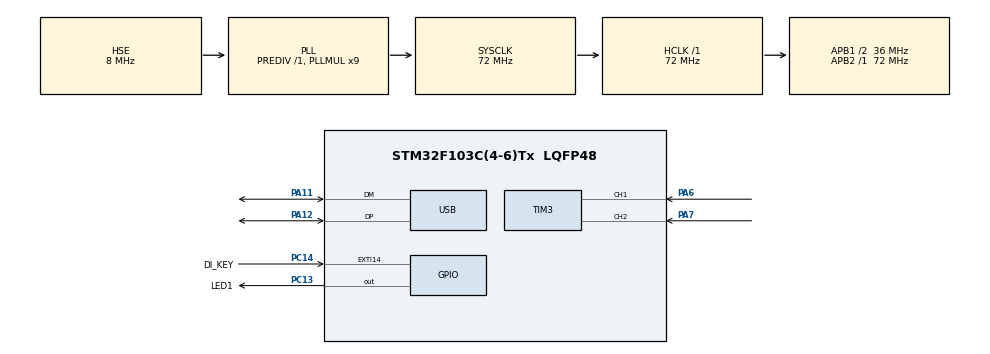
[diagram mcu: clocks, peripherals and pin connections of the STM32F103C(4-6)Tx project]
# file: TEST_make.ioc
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Mcu.Family=STM32F1
Mcu.Name=STM32F103C(4-6)Tx
Mcu.Package=LQFP48
NVIC.EXTI15_10_IRQn=true\:0\:0\:false\:false\:true\:true\:true\:true
NVIC.PriorityGroup=NVIC_PRIORITYGROUP_4
NVIC.USB_LP_CAN1_RX0_IRQn=true\:0\:0\:false\:false\:true\:false\:true\:true
PA11.Mode=Device
PA11.Signal=USB_DM
PA12.Mode=Device
PA12.Signal=USB_DP
PA13.Mode=Serial_Wire
PA13.Signal=SYS_JTMS-SWDIO
PA14.Mode=Serial_Wire
PA14.Signal=SYS_JTCK-SWCLK
PA6.Signal=S_TIM3_CH1
PA7.Signal=S_TIM3_CH2
PC13-TAMPER-RTC.GPIO_Label=LED1
PC13-TAMPER-RTC.GPIO_Speed=GPIO_SPEED_FREQ_HIGH
PC13-TAMPER-RTC.Signal=GPIO_Output
PC14-OSC32_IN.GPIO_Label=DI_KEY
PC14-OSC32_IN.GPIO_ModeDefaultEXTI=GPIO_MODE_IT_RISING
PC14-OSC32_IN.GPIO_PuPd=GPIO_PULLUP
PC14-OSC32_IN.Signal=GPXTI14
PD0-OSC_IN.Mode=HSE-External-Oscillator
PD0-OSC_IN.Signal=RCC_OSC_IN
PD1-OSC_OUT.Mode=HSE-External-Oscillator
PD1-OSC_OUT.Signal=RCC_OSC_OUT
ProjectManager.HeapSize=0x200
ProjectManager.StackSize=0x400
ProjectManager.TargetToolchain=CMake
RCC.AHBFreq_Value=72000000
RCC.APB1CLKDivider=RCC_HCLK_DIV2
RCC.APB1Freq_Value=36000000
RCC.APB1TimFreq_Value=72000000
RCC.APB2Freq_Value=72000000
RCC.APB2TimFreq_Value=72000000
RCC.HCLKFreq_Value=72000000
RCC.PLLMUL=RCC_PLL_MUL9
RCC.PLLSourceVirtual=RCC_PLLSOURCE_HSE
RCC.SYSCLKFreq_VALUE=72000000
RCC.SYSCLKSource=RCC_SYSCLKSOURCE_PLLCLK
RCC.USBFreq_Value=48000000
RCC.USBPrescaler=RCC_USBCLKSOURCE_PLL_DIV1_5
SH.S_TIM3_CH1.0=TIM3_CH1,Encoder_Interface
SH.S_TIM3_CH2.0=TIM3_CH2,Encoder_Interface
TIM3.EncoderMode=TIM_ENCODERMODE_TI12
TIM3.IC1Filter=15
USB_DEVICE.CLASS_NAME_FS=CDC
USB_DEVICE.VirtualMode=Cdc
USB_DEVICE.VirtualModeFS=Cdc_FS
VP_USB_DEVICE_VS_USB_DEVICE_CDC_FS.Mode=CDC_FS
board=custom

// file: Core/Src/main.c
/* USER CODE BEGIN Header */
/**
  ******************************************************************************
  * @file           : main.c
  * @brief          : Main program body
  ******************************************************************************
  * @attention
  *
  * Copyright (c) 2026 STMicroelectronics.
  * All rights reserved.
  *
  * This software is licensed under terms that can be found in the LICENSE file
  * in the root directory of this software component.
  * If no LICENSE file comes with this software, it is provided AS-IS.
  *
  ******************************************************************************
  */
/* USER CODE END Header */
#include "main.h"
#include "usb_device.h"

/* USER CODE BEGIN Includes */
#include "usbd_cdc_if.h"
#include "usbd_cdc.h"
#include "statemachine.h"
/* USER CODE END Includes */

TIM_HandleTypeDef htim3;

void SystemClock_Config(void);
static void MX_GPIO_Init(void);
static void MX_TIM3_Init(void);

int main(void)
{

  /* MCU Configuration--------------------------------------------------------*/

  /* Reset of all peripherals, Initializes the Flash interface and the Systick. */
  HAL_Init();

  /* Configure the system clock */
  SystemClock_Config();

  /* Initialize all configured peripherals */
  MX_GPIO_Init();
  MX_USB_DEVICE_Init();
  MX_TIM3_Init();
  /* USER CODE BEGIN 2 */
  HAL_TIM_Encoder_Start(&htim3, TIM_CHANNEL_ALL);
/*   HAL_GPIO_WritePin(LED1_GPIO_Port, LED1_Pin, GPIO_PIN_SET);
  HAL_GPIO_WritePin(LED1_GPIO_Port, LED1_Pin, GPIO_PIN_SET); */

  CDC_Transmit_FS((uint8_t *)"Hello World!\r\n", sizeof("Hello World!\r\n") - 1);
  /* USER CODE END 2 */

  /* Infinite loop */
  /* USER CODE BEGIN WHILE */
  uint32_t tick_start = HAL_GetTick();
  uint32_t time_delay = 1000; // Delay time in milliseconds
  while (1)
  {
    if (HAL_GetTick() - tick_start >= time_delay)
    {
      tick_start = HAL_GetTick();
      if (statemachine(led_toggle) == LED_ERROR)
      {
        Error_Handler();
      }
    }
    DI_KEY_check();
    digit_encoder_check();
    HAL_Delay(1); // Add a small delay to avoid busy waiting

    /* USER CODE END WHILE */

  }
}

void SystemClock_Config(void)
{
  RCC_OscInitTypeDef RCC_OscInitStruct = {0};
  RCC_ClkInitTypeDef RCC_ClkInitStruct = {0};
  RCC_PeriphCLKInitTypeDef PeriphClkInit = {0};

  /** Initializes the RCC Oscillators according to the specified parameters
  * in the RCC_OscInitTypeDef structure.
  */
  RCC_OscInitStruct.OscillatorType = RCC_OSCILLATORTYPE_HSE;
  RCC_OscInitStruct.HSEState = RCC_HSE_ON;
  RCC_OscInitStruct.HSEPredivValue = RCC_HSE_PREDIV_DIV1;
  RCC_OscInitStruct.HSIState = RCC_HSI_ON;
  RCC_OscInitStruct.PLL.PLLState = RCC_PLL_ON;
  RCC_OscInitStruct.PLL.PLLSource = RCC_PLLSOURCE_HSE;
  RCC_OscInitStruct.PLL.PLLMUL = RCC_PLL_MUL9;
  if (HAL_RCC_OscConfig(&RCC_OscInitStruct) != HAL_OK)
  {
    Error_Handler();
  }

  /** Initializes the CPU, AHB and APB buses clocks
  */
  RCC_ClkInitStruct.ClockType = RCC_CLOCKTYPE_HCLK|RCC_CLOCKTYPE_SYSCLK
                              |RCC_CLOCKTYPE_PCLK1|RCC_CLOCKTYPE_PCLK2;
  RCC_ClkInitStruct.SYSCLKSource = RCC_SYSCLKSOURCE_PLLCLK;
  RCC_ClkInitStruct.AHBCLKDivider = RCC_SYSCLK_DIV1;
  RCC_ClkInitStruct.APB1CLKDivider = RCC_HCLK_DIV2;
  RCC_ClkInitStruct.APB2CLKDivider = RCC_HCLK_DIV1;

  if (HAL_RCC_ClockConfig(&RCC_ClkInitStruct, FLASH_LATENCY_2) != HAL_OK)
  {
    Error_Handler();
  }
  PeriphClkInit.PeriphClockSelection = RCC_PERIPHCLK_USB;
  PeriphClkInit.UsbClockSelection = RCC_USBCLKSOURCE_PLL_DIV1_5;
  if (HAL_RCCEx_PeriphCLKConfig(&PeriphClkInit) != HAL_OK)
  {
    Error_Handler();
  }
}

static void MX_TIM3_Init(void)
{

  TIM_Encoder_InitTypeDef sConfig = {0};
  TIM_MasterConfigTypeDef sMasterConfig = {0};

  htim3.Instance = TIM3;
  htim3.Init.Prescaler = 0;
  htim3.Init.CounterMode = TIM_COUNTERMODE_UP;
  htim3.Init.Period = 65535;
  htim3.Init.ClockDivision = TIM_CLOCKDIVISION_DIV1;
  htim3.Init.AutoReloadPreload = TIM_AUTORELOAD_PRELOAD_DISABLE;
  sConfig.EncoderMode = TIM_ENCODERMODE_TI12;
  sConfig.IC1Polarity = TIM_ICPOLARITY_RISING;
  sConfig.IC1Selection = TIM_ICSELECTION_DIRECTTI;
  sConfig.IC1Prescaler = TIM_ICPSC_DIV1;
  sConfig.IC1Filter = 15;
  sConfig.IC2Polarity = TIM_ICPOLARITY_RISING;
  sConfig.IC2Selection = TIM_ICSELECTION_DIRECTTI;
  sConfig.IC2Prescaler = TIM_ICPSC_DIV1;
  sConfig.IC2Filter = 0;
  if (HAL_TIM_Encoder_Init(&htim3, &sConfig) != HAL_OK)
  {
    Error_Handler();
  }
  sMasterConfig.MasterOutputTrigger = TIM_TRGO_RESET;
  sMasterConfig.MasterSlaveMode = TIM_MASTERSLAVEMODE_DISABLE;
  if (HAL_TIMEx_MasterConfigSynchronization(&htim3, &sMasterConfig) != HAL_OK)
  {
    Error_Handler();
  }

}

static void MX_GPIO_Init(void)
{
  GPIO_InitTypeDef GPIO_InitStruct = {0};

  /* GPIO Ports Clock Enable */
  __HAL_RCC_GPIOC_CLK_ENABLE();
  __HAL_RCC_GPIOD_CLK_ENABLE();
  __HAL_RCC_GPIOA_CLK_ENABLE();

  /*Configure GPIO pin Output Level */
  HAL_GPIO_WritePin(LED1_GPIO_Port, LED1_Pin, GPIO_PIN_RESET);

  /*Configure GPIO pin : LED1_Pin */
  GPIO_InitStruct.Pin = LED1_Pin;
  GPIO_InitStruct.Mode = GPIO_MODE_OUTPUT_PP;
  GPIO_InitStruct.Pull = GPIO_NOPULL;
  GPIO_InitStruct.Speed = GPIO_SPEED_FREQ_HIGH;
  HAL_GPIO_Init(LED1_GPIO_Port, &GPIO_InitStruct);

  /*Configure GPIO pin : DI_KEY_Pin */
  GPIO_InitStruct.Pin = DI_KEY_Pin;
  GPIO_InitStruct.Mode = GPIO_MODE_IT_RISING;
  GPIO_InitStruct.Pull = GPIO_PULLUP;
  HAL_GPIO_Init(DI_KEY_GPIO_Port, &GPIO_InitStruct);

  /* EXTI interrupt init*/
  HAL_NVIC_SetPriority(EXTI15_10_IRQn, 0, 0);
  HAL_NVIC_EnableIRQ(EXTI15_10_IRQn);

}

void Error_Handler(void)
{
  __disable_irq();
  while (1)
  {
  }
}
